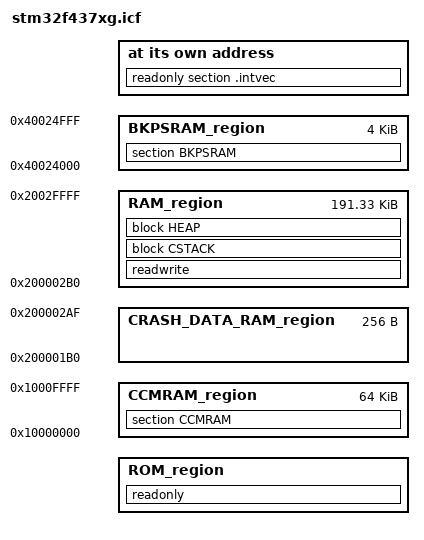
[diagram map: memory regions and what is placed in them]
/* Linker script to configure memory regions.
 *
 * SPDX-License-Identifier: BSD-3-Clause
 ******************************************************************************
 * @attention
 *
 * Copyright (c) 2016-2020 STMicroelectronics.
 * All rights reserved.
 *
 * This software component is licensed by ST under BSD 3-Clause license,
 * the "License"; You may not use this file except in compliance with the
 * License. You may obtain a copy of the License at:
 *                        opensource.org/licenses/BSD-3-Clause
 *
 ******************************************************************************
*/

if (!isdefinedsymbol(MBED_APP_START)) { define symbol MBED_APP_START = 0x08000000; }
if (!isdefinedsymbol(MBED_APP_SIZE)) { define symbol MBED_APP_SIZE = 0x100000; }
/*-Specials-*/
define symbol __ICFEDIT_intvec_start__ = MBED_APP_START;
/*-Memory Regions-*/
define symbol __ICFEDIT_region_ROM_start__     = MBED_APP_START;
define symbol __ICFEDIT_region_ROM_end__       = MBED_APP_START + MBED_APP_SIZE - 1;
define symbol __ICFEDIT_region_NVIC_start__    = 0x20000000;
define symbol __ICFEDIT_region_NVIC_end__      = 0x200001AF;
define symbol __region_CRASH_DATA_RAM_start__  = 0x200001B0;
define symbol __region_CRASH_DATA_RAM_end__    = 0x200002AF;
define symbol __ICFEDIT_region_RAM_start__     = 0x200002B0;
define symbol __ICFEDIT_region_RAM_end__       = 0x2002FFFF;
define symbol __ICFEDIT_region_CCMRAM_start__  = 0x10000000;
define symbol __ICFEDIT_region_CCMRAM_end__    = 0x1000FFFF;
define symbol __ICFEDIT_region_BKPSRAM_start__ = 0x40024000;
define symbol __ICFEDIT_region_BKPSRAM_end__   = 0x40024FFF;
/*-Sizes-*/
if (!isdefinedsymbol(MBED_CONF_TARGET_BOOT_STACK_SIZE)) {
    define symbol MBED_CONF_TARGET_BOOT_STACK_SIZE = 0x400;
}
define symbol __ICFEDIT_size_cstack__ = MBED_CONF_TARGET_BOOT_STACK_SIZE;
define symbol __ICFEDIT_size_heap__   = 0x18000;


define memory mem with size = 4G;
define region ROM_region      = mem:[from __ICFEDIT_region_ROM_start__ to __ICFEDIT_region_ROM_end__];
define region CRASH_DATA_RAM_region = mem:[from __region_CRASH_DATA_RAM_start__ to __region_CRASH_DATA_RAM_end__];
define region RAM_region      = mem:[from __ICFEDIT_region_RAM_start__ to __ICFEDIT_region_RAM_end__];
define region CCMRAM_region   = mem:[from __ICFEDIT_region_CCMRAM_start__ to __ICFEDIT_region_CCMRAM_end__];
define region BKPSRAM_region  = mem:[from __ICFEDIT_region_BKPSRAM_start__ to __ICFEDIT_region_BKPSRAM_end__];

/* Define Crash Data Symbols */
define exported symbol __CRASH_DATA_RAM_START__ = __region_CRASH_DATA_RAM_start__;
define exported symbol __CRASH_DATA_RAM_END__ = __region_CRASH_DATA_RAM_end__;

define block CSTACK    with alignment = 8, size = __ICFEDIT_size_cstack__   { };
define block HEAP      with alignment = 8, size = __ICFEDIT_size_heap__     { };

initialize by copy { readwrite };
do not initialize  { section .noinit };
do not initialize  { section CCMRAM };
do not initialize  { section BKPSRAM };

place at address mem:__ICFEDIT_intvec_start__ { readonly section .intvec };

place in ROM_region   { readonly };
place in RAM_region   { readwrite,
                        block CSTACK, block HEAP };
place in CCMRAM_region    { section CCMRAM };
place in BKPSRAM_region    { section BKPSRAM };
